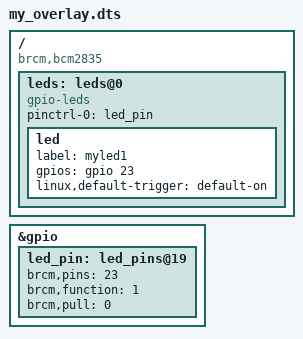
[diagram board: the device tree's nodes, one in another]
/dts-v1/;
/plugin/;

/ {
	compatible = "brcm,bcm2835";

	fragment@0 {
		// Configure the gpio pin controller
		target = <&gpio>;
		__overlay__ {
			led_pin: led_pins@19 {
				brcm,pins = <23>; // gpio number
				brcm,function = <1>; // 0 = input, 1 = output
				brcm,pull = <0>; // 0 = none, 1 = pull down, 2 = pull up
			};
		};
	};
	fragment@1 {
		target-path = "/";
		__overlay__ {
			leds: leds@0 {
				compatible = "gpio-leds";
				pinctrl-names = "default";
				pinctrl-0 = <&led_pin>;
				status = "okay";

				led: led {
			                label = "myled1";
					gpios = <&gpio 23 0>;
			                linux,default-trigger = "default-on";
				};
			};
		};
	};
};
